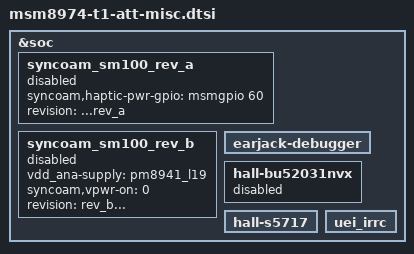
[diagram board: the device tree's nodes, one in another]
/* Copyright (c) 2012, Code Aurora Forum. All rights reserved.
 *
 * This program is free software; you can redistribute it and/or modify
 * it under the terms of the GNU General Public License version 2 and
 * only version 2 as published by the Free Software Foundation.
 *
 * This program is distributed in the hope that it will be useful,
 * but WITHOUT ANY WARRANTY; without even the implied warranty of
 * MERCHANTABILITY or FITNESS FOR A PARTICULAR PURPOSE.  See the
 * GNU General Public License for more details.
 */

&soc {
	syncoam_sm100_rev_a {
		syncoam,haptic-pwr-gpio = <&msmgpio 60 0x00>;
		status = "disable";
		revision = "...rev_a";
	};

	syncoam_sm100_rev_b {
		vdd_ana-supply = <&pm8941_l19>;
		syncoam,vpwr-on = <0>;
		status = "disable";
		revision = "rev_b...";
	};

	earjack-debugger {
		status = "ok";
	};

	hall-bu52031nvx {
		status = "disable";
	};

	hall-s5717 {
		status = "ok";
	};

	uei_irrc {
		status = "ok";
	};

};
